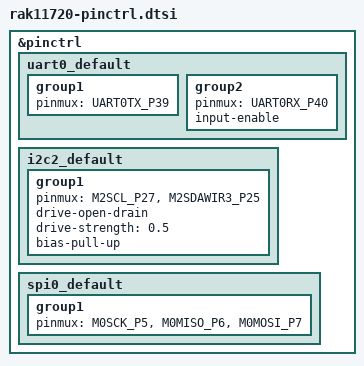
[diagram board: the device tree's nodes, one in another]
/*
 * Copyright (c) 2024 RAKwireless Technology Co., Ltd. <www.rakwireless.com>
 * Sercan Erat <sercanerat@gmail.com>
 * SPDX-License-Identifier: Apache-2.0
 */

#include <zephyr/dt-bindings/pinctrl/ambiq-apollo3-pinctrl.h>

&pinctrl {
	uart0_default: uart0_default {
		group1 {
			pinmux = <UART0TX_P39>;
		};

		group2 {
			pinmux = <UART0RX_P40>;
			input-enable;
		};
	};

	i2c2_default: i2c2_default {
		group1 {
			pinmux = <M2SCL_P27>, <M2SDAWIR3_P25>;
			drive-open-drain;
			drive-strength = "0.5";
			bias-pull-up;
		};
	};

	spi0_default: spi0_default {
		group1 {
			pinmux = <M0SCK_P5>, <M0MISO_P6>, <M0MOSI_P7>;
		};
	};
};
